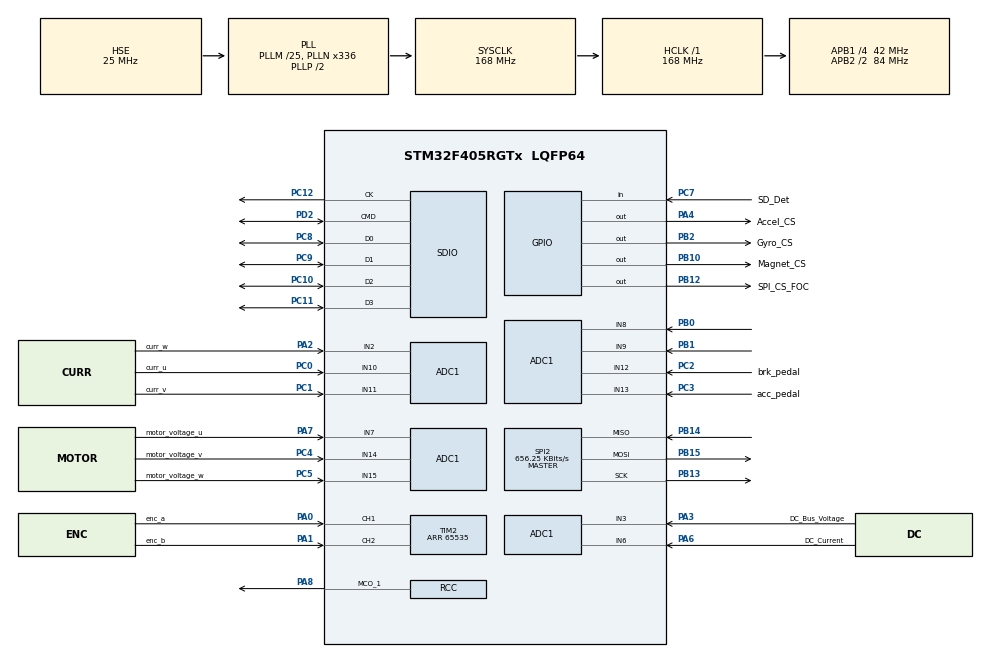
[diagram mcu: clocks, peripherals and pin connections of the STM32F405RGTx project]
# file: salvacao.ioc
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ADC1.Channel-0\#ChannelRegularConversion=ADC_CHANNEL_8
ADC1.Channel-1\#ChannelRegularConversion=ADC_CHANNEL_12
ADC1.Channel-12\#ChannelRegularConversion=ADC_CHANNEL_13
ADC1.Channel-13\#ChannelRegularConversion=ADC_CHANNEL_2
ADC1.Channel-14\#ChannelRegularConversion=ADC_CHANNEL_10
ADC1.Channel-15\#ChannelRegularConversion=ADC_CHANNEL_11
ADC1.Channel-16\#ChannelRegularConversion=ADC_CHANNEL_9
ADC1.Channel-17\#ChannelRegularConversion=ADC_CHANNEL_3
ADC1.Channel-18\#ChannelRegularConversion=ADC_CHANNEL_6
ADC1.Channel-19\#ChannelRegularConversion=ADC_CHANNEL_7
ADC1.Channel-20\#ChannelRegularConversion=ADC_CHANNEL_14
ADC1.Channel-21\#ChannelRegularConversion=ADC_CHANNEL_15
ADC1.ContinuousConvMode=ENABLE
ADC1.DMAContinuousRequests=ENABLE
ADC1.NbrOfConversion=12
ADC1.NbrOfConversionFlag=1
ADC1.Rank-0\#ChannelRegularConversion=1
ADC1.Rank-1\#ChannelRegularConversion=2
ADC1.Rank-12\#ChannelRegularConversion=3
ADC1.Rank-13\#ChannelRegularConversion=4
ADC1.Rank-14\#ChannelRegularConversion=5
ADC1.Rank-15\#ChannelRegularConversion=6
ADC1.Rank-16\#ChannelRegularConversion=7
ADC1.Rank-17\#ChannelRegularConversion=8
ADC1.Rank-18\#ChannelRegularConversion=9
ADC1.Rank-19\#ChannelRegularConversion=10
ADC1.Rank-20\#ChannelRegularConversion=11
ADC1.Rank-21\#ChannelRegularConversion=12
ADC1.SamplingTime-0\#ChannelRegularConversion=ADC_SAMPLETIME_3CYCLES
ADC1.SamplingTime-1\#ChannelRegularConversion=ADC_SAMPLETIME_3CYCLES
ADC1.SamplingTime-12\#ChannelRegularConversion=ADC_SAMPLETIME_3CYCLES
ADC1.SamplingTime-13\#ChannelRegularConversion=ADC_SAMPLETIME_3CYCLES
ADC1.SamplingTime-14\#ChannelRegularConversion=ADC_SAMPLETIME_3CYCLES
ADC1.SamplingTime-15\#ChannelRegularConversion=ADC_SAMPLETIME_3CYCLES
ADC1.SamplingTime-16\#ChannelRegularConversion=ADC_SAMPLETIME_3CYCLES
ADC1.SamplingTime-17\#ChannelRegularConversion=ADC_SAMPLETIME_3CYCLES
ADC1.SamplingTime-18\#ChannelRegularConversion=ADC_SAMPLETIME_3CYCLES
ADC1.SamplingTime-19\#ChannelRegularConversion=ADC_SAMPLETIME_3CYCLES
ADC1.SamplingTime-20\#ChannelRegularConversion=ADC_SAMPLETIME_3CYCLES
ADC1.SamplingTime-21\#ChannelRegularConversion=ADC_SAMPLETIME_3CYCLES
ADC1.ScanConvMode=ENABLE
ADC1.master=1
Dma.ADC1.0.Direction=DMA_PERIPH_TO_MEMORY
Dma.ADC1.0.FIFOMode=DMA_FIFOMODE_DISABLE
Dma.ADC1.0.Instance=DMA2_Stream0
Dma.ADC1.0.MemDataAlignment=DMA_MDATAALIGN_WORD
Dma.ADC1.0.MemInc=DMA_MINC_ENABLE
Dma.ADC1.0.Mode=DMA_CIRCULAR
Dma.ADC1.0.PeriphDataAlignment=DMA_PDATAALIGN_WORD
Dma.ADC1.0.PeriphInc=DMA_PINC_DISABLE
Dma.ADC1.0.Priority=DMA_PRIORITY_LOW
Dma.Request0=ADC1
Dma.Request1=SDIO_RX
Dma.Request2=SDIO_TX
Dma.SDIO_RX.1.Direction=DMA_PERIPH_TO_MEMORY
Dma.SDIO_RX.1.FIFOMode=DMA_FIFOMODE_ENABLE
Dma.SDIO_RX.1.FIFOThreshold=DMA_FIFO_THRESHOLD_FULL
Dma.SDIO_RX.1.Instance=DMA2_Stream3
Dma.SDIO_RX.1.MemBurst=DMA_MBURST_INC4
Dma.SDIO_RX.1.MemDataAlignment=DMA_MDATAALIGN_WORD
Dma.SDIO_RX.1.MemInc=DMA_MINC_ENABLE
Dma.SDIO_RX.1.Mode=DMA_PFCTRL
Dma.SDIO_RX.1.PeriphBurst=DMA_PBURST_INC4
Dma.SDIO_RX.1.PeriphDataAlignment=DMA_PDATAALIGN_WORD
Dma.SDIO_RX.1.PeriphInc=DMA_PINC_DISABLE
Dma.SDIO_RX.1.Priority=DMA_PRIORITY_LOW
Dma.SDIO_TX.2.Direction=DMA_MEMORY_TO_PERIPH
Dma.SDIO_TX.2.FIFOMode=DMA_FIFOMODE_ENABLE
Dma.SDIO_TX.2.FIFOThreshold=DMA_FIFO_THRESHOLD_FULL
Dma.SDIO_TX.2.Instance=DMA2_Stream6
Dma.SDIO_TX.2.MemBurst=DMA_MBURST_INC4
Dma.SDIO_TX.2.MemDataAlignment=DMA_MDATAALIGN_WORD
Dma.SDIO_TX.2.MemInc=DMA_MINC_ENABLE
Dma.SDIO_TX.2.Mode=DMA_PFCTRL
Dma.SDIO_TX.2.PeriphBurst=DMA_PBURST_INC4
Dma.SDIO_TX.2.PeriphDataAlignment=DMA_PDATAALIGN_WORD
Dma.SDIO_TX.2.PeriphInc=DMA_PINC_DISABLE
Dma.SDIO_TX.2.Priority=DMA_PRIORITY_LOW
FATFS.BSP.number=1
FATFS.USE_DMA_CODE_SD=1
FATFS._FS_LOCK=2
FATFS._MAX_SS=4096
FATFS._USE_LFN=1
FATFS0.BSP.STBoard=false
FATFS0.BSP.api=Unknown
FATFS0.BSP.i2caddr=0
FATFS0.BSP.instance=PC7
FATFS0.BSP.ip=GPIO
FATFS0.BSP.mode=Input
FATFS0.BSP.name=Detect_SDIO
FATFS0.BSP.solution=PC7
Mcu.Family=STM32F4
Mcu.Name=STM32F405RGTx
Mcu.Package=LQFP64
NVIC.DMA2_Stream0_IRQn=true\:0\:0\:false\:false\:true\:false\:true
NVIC.DMA2_Stream3_IRQn=true\:0\:0\:false\:false\:true\:false\:true
NVIC.DMA2_Stream6_IRQn=true\:0\:0\:false\:false\:true\:false\:true
NVIC.PriorityGroup=NVIC_PRIORITYGROUP_4
NVIC.SDIO_IRQn=true\:0\:0\:true\:false\:true\:true\:true
NVIC.TIM6_DAC_IRQn=true\:0\:0\:false\:false\:true\:true\:true
PA0-WKUP.GPIO_Label=enc_a
PA0-WKUP.Signal=S_TIM2_CH1_ETR
PA1.GPIO_Label=enc_b
PA1.Signal=S_TIM2_CH2
PA13.Mode=Trace_Asynchronous_SW
PA13.Signal=SYS_JTMS-SWDIO
PA14.Mode=Trace_Asynchronous_SW
PA14.Signal=SYS_JTCK-SWCLK
PA2.GPIO_Label=curr_w
PA2.Signal=ADCx_IN2
PA3.GPIO_Label=DC_Bus_Voltage
PA3.Signal=ADCx_IN3
PA4.GPIO_Label=Accel_CS
PA4.Signal=GPIO_Output
PA6.GPIO_Label=DC_Current
PA6.Signal=ADCx_IN6
PA7.GPIO_Label=motor_voltage_u
PA7.Signal=ADCx_IN7
PA8.Mode=Clock-out-1
PA8.Signal=RCC_MCO_1
PB0.Signal=ADCx_IN8
PB1.Signal=ADCx_IN9
PB10.GPIO_Label=Magnet_CS
PB10.Signal=GPIO_Output
PB12.GPIO_Label=SPI_CS_FOC
PB12.Signal=GPIO_Output
PB13.Mode=Full_Duplex_Master
PB13.Signal=SPI2_SCK
PB14.Mode=Full_Duplex_Master
PB14.Signal=SPI2_MISO
PB15.Mode=Full_Duplex_Master
PB15.Signal=SPI2_MOSI
PB2.GPIO_Label=Gyro_CS
PB2.Signal=GPIO_Output
PB3.Mode=Trace_Asynchronous_SW
PB3.Signal=SYS_JTDO-SWO
PC0.GPIO_Label=curr_u
PC0.Signal=ADCx_IN10
PC1.GPIO_Label=curr_v
PC1.Signal=ADCx_IN11
PC10.GPIO_PuPd=GPIO_NOPULL
PC10.Mode=SD_4_bits_Wide_bus
PC10.Signal=SDIO_D2
PC11.GPIO_PuPd=GPIO_NOPULL
PC11.Mode=SD_4_bits_Wide_bus
PC11.Signal=SDIO_D3
PC12.Mode=SD_4_bits_Wide_bus
PC12.Signal=SDIO_CK
PC14-OSC32_IN.Mode=LSE-External-Oscillator
PC14-OSC32_IN.Signal=RCC_OSC32_IN
PC15-OSC32_OUT.Mode=LSE-External-Oscillator
PC15-OSC32_OUT.Signal=RCC_OSC32_OUT
PC2.GPIO_Label=brk_pedal
PC2.Signal=ADCx_IN12
PC3.GPIO_Label=acc_pedal
PC3.Signal=ADCx_IN13
PC4.GPIO_Label=motor_voltage_v
PC4.Signal=ADCx_IN14
PC5.GPIO_Label=motor_voltage_w
PC5.Signal=ADCx_IN15
PC7.GPIO_Label=SD_Det
PC7.GPIO_PuPd=GPIO_NOPULL
PC7.Signal=GPIO_Input
PC8.GPIO_PuPd=GPIO_PULLUP
PC8.Mode=SD_4_bits_Wide_bus
PC8.Signal=SDIO_D0
PC9.GPIO_PuPd=GPIO_NOPULL
PC9.Mode=SD_4_bits_Wide_bus
PC9.Signal=SDIO_D1
PD2.GPIO_PuPd=GPIO_PULLUP
PD2.Mode=SD_4_bits_Wide_bus
PD2.Signal=SDIO_CMD
PH0-OSC_IN.Mode=HSE-External-Oscillator
PH0-OSC_IN.Signal=RCC_OSC_IN
PH1-OSC_OUT.Mode=HSE-External-Oscillator
PH1-OSC_OUT.Signal=RCC_OSC_OUT
ProjectManager.HeapSize=0x8000
ProjectManager.StackSize=0x8000
ProjectManager.TargetToolchain=STM32CubeIDE
RCC.48MHZClocksFreq_Value=48000000
RCC.AHBFreq_Value=168000000
RCC.APB1CLKDivider=RCC_HCLK_DIV4
RCC.APB1Freq_Value=42000000
RCC.APB1TimFreq_Value=84000000
RCC.APB2CLKDivider=RCC_HCLK_DIV2
RCC.APB2Freq_Value=84000000
RCC.APB2TimFreq_Value=168000000
RCC.CortexFreq_Value=168000000
RCC.HCLKFreq_Value=168000000
RCC.HSE_VALUE=25000000
RCC.HSI_VALUE=16000000
RCC.PLLM=25
RCC.PLLN=336
RCC.PLLQ=7
RCC.PLLSourceVirtual=RCC_PLLSOURCE_HSE
RCC.RCC_MCO1Source=RCC_MCO1SOURCE_HSE
RCC.RCC_MCODiv1=RCC_MCODIV_2
RCC.SYSCLKFreq_VALUE=168000000
RCC.SYSCLKSource=RCC_SYSCLKSOURCE_PLLCLK
RCC.VCOOutputFreq_Value=336000000
SDIO.ClockDiv=1
SH.ADCx_IN10.0=ADC1_IN10,IN10
SH.ADCx_IN11.0=ADC1_IN11,IN11
SH.ADCx_IN12.0=ADC1_IN12,IN12
SH.ADCx_IN13.0=ADC1_IN13,IN13
SH.ADCx_IN14.0=ADC1_IN14,IN14
SH.ADCx_IN15.0=ADC1_IN15,IN15
SH.ADCx_IN2.0=ADC1_IN2,IN2
SH.ADCx_IN3.0=ADC1_IN3,IN3
SH.ADCx_IN6.0=ADC1_IN6,IN6
SH.ADCx_IN7.0=ADC1_IN7,IN7
SH.ADCx_IN8.0=ADC1_IN8,IN8
SH.ADCx_IN9.0=ADC1_IN9,IN9
SH.S_TIM2_CH1_ETR.0=TIM2_CH1,Encoder_Interface
SH.S_TIM2_CH2.0=TIM2_CH2,Encoder_Interface
SPI2.BaudRatePrescaler=SPI_BAUDRATEPRESCALER_64
SPI2.CLKPhase=SPI_PHASE_2EDGE
SPI2.CLKPolarity=SPI_POLARITY_HIGH
SPI2.CalculateBaudRate=656.25 KBits/s
SPI2.Direction=SPI_DIRECTION_2LINES
SPI2.Mode=SPI_MODE_MASTER
SPI2.VirtualType=VM_MASTER
TIM2.EncoderMode=TIM_ENCODERMODE_TI12
TIM2.Period=65535
TIM6.Period=2000
TIM6.Prescaler=42000
TIM6.TIM_MasterOutputTrigger=TIM_TRGO_UPDATE
VP_FATFS_VS_SDIO.Mode=SDIO
VP_TIM6_VS_ClockSourceINT.Mode=Enable_Timer
board=custom

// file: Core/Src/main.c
/* USER CODE BEGIN Header */
/**
  ******************************************************************************
  * @file           : main.c
  * @brief          : Main program body
  ******************************************************************************
  * @attention
  *
  * <h2><center>&copy; Copyright (c) 2020 STMicroelectronics.
  * All rights reserved.</center></h2>
  *
  * This software component is licensed by ST under BSD 3-Clause license,
  * the "License"; You may not use this file except in compliance with the
  * License. You may obtain a copy of the License at:
  *                        opensource.org/licenses/BSD-3-Clause
  *
  ******************************************************************************
  */
/* USER CODE END Header */

#include "main.h"
#include "fatfs.h"

/* USER CODE BEGIN Includes */
#include "stdio.h"
#include "sd_wr.h"
#include "IMU_read.h"
#include "encoderMode.h"
#include "adcUnitConversion.h"
#include "FOC_lib.h"
/* USER CODE END Includes */

/* USER CODE BEGIN PD */

#define	NR_ADC_CHANNELS 12 //Nº de channels adc
#define TICK_RATE 1 //milisecond

/* USER CODE END PD */

ADC_HandleTypeDef hadc1;
DMA_HandleTypeDef hdma_adc1;

SD_HandleTypeDef hsd;
DMA_HandleTypeDef hdma_sdio_rx;
DMA_HandleTypeDef hdma_sdio_tx;

SPI_HandleTypeDef hspi2;

TIM_HandleTypeDef htim2;
TIM_HandleTypeDef htim6;

/* USER CODE BEGIN PV */

volatile unsigned long SystemTick=0;
volatile unsigned long __unix_ms=0;
volatile unsigned long __unix_sec=0;

uint32_t adc_dma[NR_ADC_CHANNELS], buffer_dma[NR_ADC_CHANNELS];

//SD file variables
	FATFS fs;  // file system
	FIL fil, fil2, fil3;  // file
	FRESULT fresult;  // to store the result
	char buffer[512]; // to store data

	UINT br, bw;   // file read/write count

	/* capacity related variables */
	//DWORD fre_clust;
	DWORD total, free_space;

//Encoder mode variables
	uint32_t counter1 = 0, counter2 = 0;
	uint32_t tick = 0;
	float speed = 0;

//IMU accelerometer data
	int accel_data[3];
//IMU accelerometer data
	int gyro_data[3];
	long int c1;

	float dc_current, current_ph1, current_ph2, current_ph3, dc_voltage, voltage_ph1, voltage_ph2, voltage_ph3,  motor_temp, conv_temp, acc_pedal , brk_pedal;

	float rms_current_ph1[10] = {-1,-1,-1,-1,-1,-1,-1,-1,-1,-1};
	float rms_current_ph2[10] = {-1,-1,-1,-1,-1,-1,-1,-1,-1,-1};
	float rms_current_ph3[10] = {-1,-1,-1,-1,-1,-1,-1,-1,-1,-1};
	float rms_voltage[10]     = {-1,-1,-1,-1,-1,-1,-1,-1,-1,-1};

	float current1_rms = 0;
	float current2_rms = 0;
	float current3_rms = 0;
	float voltage1_rms = 0;
	float voltage2_rms = 0;
	float voltage3_rms = 0;

	int f = 0;

//encoder
/*	int stateA = 0, stateB = 0, stateM = 0, pstateA = 0, pstateB = 0, pstate = 0, pulses = 0;
	int dir = 0; // 0 forward -1 otherwise*/

	char stamp[100];

	//teste
	uint32_t time2;

//microsegundos
	uint32_t micro = 0, mili = 0, seg = 0;

/* USER CODE END PV */

void SystemClock_Config(void);
static void MX_GPIO_Init(void);
static void MX_DMA_Init(void);
static void MX_SPI2_Init(void);
static void MX_ADC1_Init(void);
static void MX_SDIO_SD_Init(void);
static void MX_TIM6_Init(void);
static void MX_TIM2_Init(void);

/* USER CODE BEGIN 0 */

void HAL_ADC_ConvCpltCallback(ADC_HandleTypeDef* hadc)
{
	//printf("dma timer = %lu\n", HAL_GetTick()-time2);
	if(hadc->Instance == ADC1){
		for(int i=0; i < NR_ADC_CHANNELS; i++)
			{
				adc_dma[i]=buffer_dma[i];
			}
	}
	//time2 = HAL_GetTick();
}

void HAL_TIM_PeriodElapsedCallback(TIM_HandleTypeDef *htim){

	//UNUSED(htim); será preciso?

	//counter2 = __HAL_TIM_GET_COUNTER(&htim2);
	//printf("%lu\n", HAL_GetTick());
	if(htim->Instance== TIM6){
		printf("kay\n");
		speed = motorSpeed(&counter1, &tick, htim2);
	}
	/*if(htim->Instance == TIM7) {
		//printf("hello7\n");
		micro++;
		if(micro >= 1000){
			micro -= 1000;
			if(mili == 999){
				mili = 0;
				seg++;
			}
			else mili++;
		}
	}*/

	/* passa a fazer-se aqui?
	sprintf(str, "%f ", speed);
	update_file("encoder_data.txt", str, get_timestamp(&hrtc, &currentTime, &currentDate), stamp, &(fil[12]), &bw); */

	/*float T = 0.25; //assumindo que periodo é 250ms
	speed = ((pulses/8)*60)/T;
	pulses = 0;*/

}

/* USER CODE END 0 */

int main(void)
{

  /* MCU Configuration--------------------------------------------------------*/

  /* Reset of all peripherals, Initializes the Flash interface and the Systick. */
  HAL_Init();

  /* Configure the system clock */
  SystemClock_Config();

  /* Initialize all configured peripherals */
  MX_GPIO_Init();
  MX_DMA_Init();
  MX_SPI2_Init();
  MX_ADC1_Init();
  MX_SDIO_SD_Init();
  MX_FATFS_Init();
  MX_TIM6_Init();
  MX_TIM2_Init();
  /* USER CODE BEGIN 2 */

  HAL_GPIO_WritePin(Accel_CS_GPIO_Port, Accel_CS_Pin, SET);
  HAL_GPIO_WritePin(Gyro_CS_GPIO_Port, Gyro_CS_Pin, SET);
  HAL_GPIO_WritePin(Magnet_CS_GPIO_Port, Magnet_CS_Pin, SET);
  HAL_GPIO_WritePin(SPI_CS_FOC_GPIO_Port, SPI_CS_FOC_Pin, SET);

  foc_ic_config(&hspi2);

  fresult=mount_card(&fs);

  char str2[30];

  IMU_config(&hspi2);

  HAL_TIM_Base_Start_IT(&htim6);
  //HAL_TIM_Base_Start_IT(&htim7);

  //Initialize encoder mode
  HAL_TIM_Encoder_Start(&htim2, TIM_CHANNEL_ALL);
  tick = HAL_GetTick();
  counter1 = __HAL_TIM_GET_COUNTER(&htim2);

  uint8_t aux[5], aux2[1], aux3[1], str3[4], str[5];
  //uint8_t ref[5];
    aux[0]=0b10000001;
    for(int i=1; i<=4; i++){
  	  aux[i]=0b00000000;
    }
    aux2[0]=0b00000000;

    time2 = HAL_GetTick();
	HAL_ADC_Start_DMA(&hadc1, buffer_dma, NR_ADC_CHANNELS);

  /* USER CODE END 2 */

  /* Infinite loop */
  while (1)
  {

    /* USER CODE BEGIN 3 */

	  printf("acc %f\n", acc_pedal);
	  if(brk_pedal > 15){
		  foc_ic_send_torque(&hspi2, 0, -1);
	  }
	  else{
		  foc_ic_send_torque(&hspi2, 30000, acc_pedal);
	  }

	  uint32_t time1 = HAL_GetTick();

	  //printf("Microssegundos = %lu\n", seg);
	  uint32_t read=adc_dma[0];
	  motor_temp = motorTemp(read);

	  read=adc_dma[1];
	  brk_pedal = pedalPos(read);

	  read=adc_dma[2];
	  acc_pedal = pedalPos(read);

	  read=adc_dma[3];
	  current_ph1 = motorCurrent(read);
	  rms_current_ph1[f] = current_ph1*current_ph1;

	  read=adc_dma[4];
	  current_ph2 = motorCurrent(read);
	  rms_current_ph2[f] = current_ph2*current_ph2;

	  read=adc_dma[5];
	  current_ph3 = motorCurrent(read);
	  rms_current_ph3[f] = current_ph3*current_ph3;

	  read=adc_dma[6];
	  conv_temp = igbtTemp(read);

	  read=adc_dma[7];
	  dc_voltage=voltageDC(read);

	  read=adc_dma[8];
	  dc_current=motorCurrent(read); //função corrente dc?

	  read=adc_dma[9];
	  voltage_ph1=voltageAC(read);

	  read=adc_dma[10];
	  voltage_ph2=voltageAC(read);

	  read=adc_dma[11];
	  voltage_ph3=voltageAC(read);

	 /* //leitura do encoder
	  read = adc_dma[12]; //encoder signal A
	  stateA = stateValue(read);

	  read = adc_dma[13]; //encoder signal B
	  stateB = stateValue(read);

	  if((stateA != pstateA) || (stateB != pstateB)){
		  if(stateA != pstateA){
			  pstateA = stateA;
		  }
		  if (stateB != pstateB){
			  pstateB = stateB;
		  }
		  updateCounter(stateA, stateB, &pstate, &dir, &pulses);
	  }

	  if(f==4){
		  current1_rms = rms(rms_current_ph1);
		  f=0;
	  }
	  else{
		  f++;
	  }*/

/*
 *
	  if(acc>50){
		  ref[0]
		  HAL_GPIO_WritePin(SPI_CS_FOC_GPIO_Port, SPI_CS_FOC_Pin, RESET);
		  HAL_SPI_Transmit(&hspi2, ref, 5, 1000);
		  HAL_GPIO_WritePin(SPI_CS_FOC_GPIO_Port, SPI_CS_FOC_Pin, SET);
	  }
	  else if(brk>50)*/

	  HAL_GPIO_WritePin(SPI_CS_FOC_GPIO_Port, SPI_CS_FOC_Pin, RESET);
	  HAL_SPI_Transmit(&hspi2, aux, 5, 1000);
	  HAL_GPIO_WritePin(SPI_CS_FOC_GPIO_Port, SPI_CS_FOC_Pin, SET);

	  HAL_GPIO_WritePin(SPI_CS_FOC_GPIO_Port, SPI_CS_FOC_Pin, RESET);
	  HAL_SPI_Transmit(&hspi2, aux2, 1, 1000);
	  HAL_SPI_Receive(&hspi2, str, 4, 1000);
	  HAL_GPIO_WritePin(SPI_CS_FOC_GPIO_Port, SPI_CS_FOC_Pin, SET);
	  //printf("%d %d %d %d\n", str[0], str[1], str[2], str[3]);

	  //ler velocidades do tmc
	  aux3[0]=0x6A;
	  HAL_GPIO_WritePin(SPI_CS_FOC_GPIO_Port, SPI_CS_FOC_Pin, RESET);
	  HAL_SPI_Transmit(&hspi2, aux3, 1, 1000);
	  HAL_SPI_Receive(&hspi2, str3, 4, 1000);
	  HAL_GPIO_WritePin(SPI_CS_FOC_GPIO_Port, SPI_CS_FOC_Pin, SET);
	  //printf("PID VELOCITY ACTUAL: %d %d %d %d\n", str3[0], str3[1], str3[2], str3[3]);

	  aux3[0]=0x22;
	  HAL_GPIO_WritePin(SPI_CS_FOC_GPIO_Port, SPI_CS_FOC_Pin, RESET);
	  HAL_SPI_Transmit(&hspi2, aux3, 1, 1000);
	  HAL_SPI_Receive(&hspi2, str3, 4, 1000);
	  HAL_GPIO_WritePin(SPI_CS_FOC_GPIO_Port, SPI_CS_FOC_Pin, SET);
	  printf("OPENLOOP VELOCITY ACTUAL: %d %d %d %d\n", str3[0], str3[1], str3[2], str3[3]);

	  aux3[0]=0x41;
	  HAL_GPIO_WritePin(SPI_CS_FOC_GPIO_Port, SPI_CS_FOC_Pin, RESET);
	  HAL_SPI_Transmit(&hspi2, aux3, 1, 1000);
	  HAL_SPI_Receive(&hspi2, str3, 4, 1000);
	  HAL_GPIO_WritePin(SPI_CS_FOC_GPIO_Port, SPI_CS_FOC_Pin, SET);
	  //printf("AENC DECODER COUNT: %d %d %d %d\n", str3[0], str3[1], str3[2], str3[3]);	   */

	  sprintf(str2,"%f ", brk_pedal);
	  sprintf(stamp, "%lu:%lu",  __unix_sec,  __unix_ms);
	  update_file("brake.txt", str2, stamp, "", &fil2, &bw);
	  stamp[0]='\0';

	  sprintf(str2,"%f ", acc_pedal);
	  sprintf(stamp, "%lu:%lu",  __unix_sec,  __unix_ms);
	  update_file("throttle.txt", str2, stamp, "", &fil2, &bw);
	  stamp[0]='\0';

	  IMU_acc_read(&hspi2, accel_data);
	  for(int i=0; i<=2; i++){
		  sprintf(str2, "accel[%d] - %d ", i, accel_data[i]);
		  sprintf(stamp, "%lu:%lu",  __unix_sec,  __unix_ms);
		  update_file("acc.txt", str2, stamp, "", &fil2, &bw);
		  stamp[0]='\0';
	  }

	  IMU_gyro_read(&hspi2, gyro_data);
	  for(int i=0; i<=2; i++){
		  sprintf(str2, "gyro[%d] - %d ", i, gyro_data[i]);
		  sprintf(stamp, "%lu:%lu",  __unix_sec,  __unix_ms);
		  update_file("gyro.txt", str2, stamp, "", &fil2, &bw);
		  stamp[0]='\0';
	  }

	  printf("tempo de ciclo = %lu\n", (HAL_GetTick() - time1));

  }

  /* USER CODE END 3 */
}

void SystemClock_Config(void)
{
  RCC_OscInitTypeDef RCC_OscInitStruct = {0};
  RCC_ClkInitTypeDef RCC_ClkInitStruct = {0};

  /** Configure the main internal regulator output voltage
  */
  __HAL_RCC_PWR_CLK_ENABLE();
  __HAL_PWR_VOLTAGESCALING_CONFIG(PWR_REGULATOR_VOLTAGE_SCALE1);
  /** Initializes the CPU, AHB and APB busses clocks
  */
  RCC_OscInitStruct.OscillatorType = RCC_OSCILLATORTYPE_HSE;
  RCC_OscInitStruct.HSEState = RCC_HSE_ON;
  RCC_OscInitStruct.PLL.PLLState = RCC_PLL_ON;
  RCC_OscInitStruct.PLL.PLLSource = RCC_PLLSOURCE_HSE;
  RCC_OscInitStruct.PLL.PLLM = 25;
  RCC_OscInitStruct.PLL.PLLN = 336;
  RCC_OscInitStruct.PLL.PLLP = RCC_PLLP_DIV2;
  RCC_OscInitStruct.PLL.PLLQ = 7;
  if (HAL_RCC_OscConfig(&RCC_OscInitStruct) != HAL_OK)
  {
    Error_Handler();
  }
  /** Initializes the CPU, AHB and APB busses clocks
  */
  RCC_ClkInitStruct.ClockType = RCC_CLOCKTYPE_HCLK|RCC_CLOCKTYPE_SYSCLK
                              |RCC_CLOCKTYPE_PCLK1|RCC_CLOCKTYPE_PCLK2;
  RCC_ClkInitStruct.SYSCLKSource = RCC_SYSCLKSOURCE_PLLCLK;
  RCC_ClkInitStruct.AHBCLKDivider = RCC_SYSCLK_DIV1;
  RCC_ClkInitStruct.APB1CLKDivider = RCC_HCLK_DIV4;
  RCC_ClkInitStruct.APB2CLKDivider = RCC_HCLK_DIV2;

  if (HAL_RCC_ClockConfig(&RCC_ClkInitStruct, FLASH_LATENCY_5) != HAL_OK)
  {
    Error_Handler();
  }
  HAL_RCC_MCOConfig(RCC_MCO1, RCC_MCO1SOURCE_HSE, RCC_MCODIV_2);
}

static void MX_ADC1_Init(void)
{

  ADC_ChannelConfTypeDef sConfig = {0};

  /** Configure the global features of the ADC (Clock, Resolution, Data Alignment and number of conversion)
  */
  hadc1.Instance = ADC1;
  hadc1.Init.ClockPrescaler = ADC_CLOCK_SYNC_PCLK_DIV4;
  hadc1.Init.Resolution = ADC_RESOLUTION_12B;
  hadc1.Init.ScanConvMode = ENABLE;
  hadc1.Init.ContinuousConvMode = ENABLE;
  hadc1.Init.DiscontinuousConvMode = DISABLE;
  hadc1.Init.ExternalTrigConvEdge = ADC_EXTERNALTRIGCONVEDGE_NONE;
  hadc1.Init.ExternalTrigConv = ADC_SOFTWARE_START;
  hadc1.Init.DataAlign = ADC_DATAALIGN_RIGHT;
  hadc1.Init.NbrOfConversion = 12;
  hadc1.Init.DMAContinuousRequests = ENABLE;
  hadc1.Init.EOCSelection = ADC_EOC_SINGLE_CONV;
  if (HAL_ADC_Init(&hadc1) != HAL_OK)
  {
    Error_Handler();
  }
  /** Configure for the selected ADC regular channel its corresponding rank in the sequencer and its sample time.
  */
  sConfig.Channel = ADC_CHANNEL_8;
  sConfig.Rank = 1;
  sConfig.SamplingTime = ADC_SAMPLETIME_3CYCLES;
  if (HAL_ADC_ConfigChannel(&hadc1, &sConfig) != HAL_OK)
  {
    Error_Handler();
  }
  /** Configure for the selected ADC regular channel its corresponding rank in the sequencer and its sample time.
  */
  sConfig.Channel = ADC_CHANNEL_12;
  sConfig.Rank = 2;
  if (HAL_ADC_ConfigChannel(&hadc1, &sConfig) != HAL_OK)
  {
    Error_Handler();
  }
  /** Configure for the selected ADC regular channel its corresponding rank in the sequencer and its sample time.
  */
  sConfig.Channel = ADC_CHANNEL_13;
  sConfig.Rank = 3;
  if (HAL_ADC_ConfigChannel(&hadc1, &sConfig) != HAL_OK)
  {
    Error_Handler();
  }
  /** Configure for the selected ADC regular channel its corresponding rank in the sequencer and its sample time.
  */
  sConfig.Channel = ADC_CHANNEL_2;
  sConfig.Rank = 4;
  if (HAL_ADC_ConfigChannel(&hadc1, &sConfig) != HAL_OK)
  {
    Error_Handler();
  }
  /** Configure for the selected ADC regular channel its corresponding rank in the sequencer and its sample time.
  */
  sConfig.Channel = ADC_CHANNEL_10;
  sConfig.Rank = 5;
  if (HAL_ADC_ConfigChannel(&hadc1, &sConfig) != HAL_OK)
  {
    Error_Handler();
  }
  /** Configure for the selected ADC regular channel its corresponding rank in the sequencer and its sample time.
  */
  sConfig.Channel = ADC_CHANNEL_11;
  sConfig.Rank = 6;
  if (HAL_ADC_ConfigChannel(&hadc1, &sConfig) != HAL_OK)
  {
    Error_Handler();
  }
  /** Configure for the selected ADC regular channel its corresponding rank in the sequencer and its sample time.
  */
  sConfig.Channel = ADC_CHANNEL_9;
  sConfig.Rank = 7;
  if (HAL_ADC_ConfigChannel(&hadc1, &sConfig) != HAL_OK)
  {
    Error_Handler();
  }
  /** Configure for the selected ADC regular channel its corresponding rank in the sequencer and its sample time.
  */
  sConfig.Channel = ADC_CHANNEL_3;
  sConfig.Rank = 8;
  if (HAL_ADC_ConfigChannel(&hadc1, &sConfig) != HAL_OK)
  {
    Error_Handler();
  }
  /** Configure for the selected ADC regular channel its corresponding rank in the sequencer and its sample time.
  */
  sConfig.Channel = ADC_CHANNEL_6;
  sConfig.Rank = 9;
  if (HAL_ADC_ConfigChannel(&hadc1, &sConfig) != HAL_OK)
  {
    Error_Handler();
  }
  /** Configure for the selected ADC regular channel its corresponding rank in the sequencer and its sample time.
  */
  sConfig.Channel = ADC_CHANNEL_7;
  sConfig.Rank = 10;
  if (HAL_ADC_ConfigChannel(&hadc1, &sConfig) != HAL_OK)
  {
    Error_Handler();
  }
  /** Configure for the selected ADC regular channel its corresponding rank in the sequencer and its sample time.
  */
  sConfig.Channel = ADC_CHANNEL_14;
  sConfig.Rank = 11;
  if (HAL_ADC_ConfigChannel(&hadc1, &sConfig) != HAL_OK)
  {
    Error_Handler();
  }
  /** Configure for the selected ADC regular channel its corresponding rank in the sequencer and its sample time.
  */
  sConfig.Channel = ADC_CHANNEL_15;
  sConfig.Rank = 12;
  if (HAL_ADC_ConfigChannel(&hadc1, &sConfig) != HAL_OK)
  {
    Error_Handler();
  }

}

static void MX_SDIO_SD_Init(void)
{

  hsd.Instance = SDIO;
  hsd.Init.ClockEdge = SDIO_CLOCK_EDGE_RISING;
  hsd.Init.ClockBypass = SDIO_CLOCK_BYPASS_DISABLE;
  hsd.Init.ClockPowerSave = SDIO_CLOCK_POWER_SAVE_DISABLE;
  hsd.Init.BusWide = SDIO_BUS_WIDE_1B;
  hsd.Init.HardwareFlowControl = SDIO_HARDWARE_FLOW_CONTROL_DISABLE;
  hsd.Init.ClockDiv = 1;

}

static void MX_SPI2_Init(void)
{

  /* SPI2 parameter configuration*/
  hspi2.Instance = SPI2;
  hspi2.Init.Mode = SPI_MODE_MASTER;
  hspi2.Init.Direction = SPI_DIRECTION_2LINES;
  hspi2.Init.DataSize = SPI_DATASIZE_8BIT;
  hspi2.Init.CLKPolarity = SPI_POLARITY_HIGH;
  hspi2.Init.CLKPhase = SPI_PHASE_2EDGE;
  hspi2.Init.NSS = SPI_NSS_SOFT;
  hspi2.Init.BaudRatePrescaler = SPI_BAUDRATEPRESCALER_64;
  hspi2.Init.FirstBit = SPI_FIRSTBIT_MSB;
  hspi2.Init.TIMode = SPI_TIMODE_DISABLE;
  hspi2.Init.CRCCalculation = SPI_CRCCALCULATION_DISABLE;
  hspi2.Init.CRCPolynomial = 10;
  if (HAL_SPI_Init(&hspi2) != HAL_OK)
  {
    Error_Handler();
  }

}

static void MX_TIM2_Init(void)
{

  TIM_Encoder_InitTypeDef sConfig = {0};
  TIM_MasterConfigTypeDef sMasterConfig = {0};

  htim2.Instance = TIM2;
  htim2.Init.Prescaler = 0;
  htim2.Init.CounterMode = TIM_COUNTERMODE_UP;
  htim2.Init.Period = 65535;
  htim2.Init.ClockDivision = TIM_CLOCKDIVISION_DIV1;
  htim2.Init.AutoReloadPreload = TIM_AUTORELOAD_PRELOAD_DISABLE;
  sConfig.EncoderMode = TIM_ENCODERMODE_TI12;
  sConfig.IC1Polarity = TIM_ICPOLARITY_RISING;
  sConfig.IC1Selection = TIM_ICSELECTION_DIRECTTI;
  sConfig.IC1Prescaler = TIM_ICPSC_DIV1;
  sConfig.IC1Filter = 0;
  sConfig.IC2Polarity = TIM_ICPOLARITY_RISING;
  sConfig.IC2Selection = TIM_ICSELECTION_DIRECTTI;
  sConfig.IC2Prescaler = TIM_ICPSC_DIV1;
  sConfig.IC2Filter = 0;
  if (HAL_TIM_Encoder_Init(&htim2, &sConfig) != HAL_OK)
  {
    Error_Handler();
  }
  sMasterConfig.MasterOutputTrigger = TIM_TRGO_RESET;
  sMasterConfig.MasterSlaveMode = TIM_MASTERSLAVEMODE_DISABLE;
  if (HAL_TIMEx_MasterConfigSynchronization(&htim2, &sMasterConfig) != HAL_OK)
  {
    Error_Handler();
  }

}

static void MX_TIM6_Init(void)
{

  TIM_MasterConfigTypeDef sMasterConfig = {0};

  htim6.Instance = TIM6;
  htim6.Init.Prescaler = 42000;
  htim6.Init.CounterMode = TIM_COUNTERMODE_UP;
  htim6.Init.Period = 2000;
  htim6.Init.AutoReloadPreload = TIM_AUTORELOAD_PRELOAD_DISABLE;
  if (HAL_TIM_Base_Init(&htim6) != HAL_OK)
  {
    Error_Handler();
  }
  sMasterConfig.MasterOutputTrigger = TIM_TRGO_UPDATE;
  sMasterConfig.MasterSlaveMode = TIM_MASTERSLAVEMODE_DISABLE;
  if (HAL_TIMEx_MasterConfigSynchronization(&htim6, &sMasterConfig) != HAL_OK)
  {
    Error_Handler();
  }

}

static void MX_DMA_Init(void)
{

  /* DMA controller clock enable */
  __HAL_RCC_DMA2_CLK_ENABLE();

  /* DMA interrupt init */
  /* DMA2_Stream0_IRQn interrupt configuration */
  HAL_NVIC_SetPriority(DMA2_Stream0_IRQn, 0, 0);
  HAL_NVIC_EnableIRQ(DMA2_Stream0_IRQn);
  /* DMA2_Stream3_IRQn interrupt configuration */
  HAL_NVIC_SetPriority(DMA2_Stream3_IRQn, 0, 0);
  HAL_NVIC_EnableIRQ(DMA2_Stream3_IRQn);
  /* DMA2_Stream6_IRQn interrupt configuration */
  HAL_NVIC_SetPriority(DMA2_Stream6_IRQn, 0, 0);
  HAL_NVIC_EnableIRQ(DMA2_Stream6_IRQn);

}

static void MX_GPIO_Init(void)
{
  GPIO_InitTypeDef GPIO_InitStruct = {0};

  /* GPIO Ports Clock Enable */
  __HAL_RCC_GPIOC_CLK_ENABLE();
  __HAL_RCC_GPIOH_CLK_ENABLE();
  __HAL_RCC_GPIOA_CLK_ENABLE();
  __HAL_RCC_GPIOB_CLK_ENABLE();
  __HAL_RCC_GPIOD_CLK_ENABLE();

  /*Configure GPIO pin Output Level */
  HAL_GPIO_WritePin(Accel_CS_GPIO_Port, Accel_CS_Pin, GPIO_PIN_RESET);

  /*Configure GPIO pin Output Level */
  HAL_GPIO_WritePin(GPIOB, Gyro_CS_Pin|Magnet_CS_Pin|SPI_CS_FOC_Pin, GPIO_PIN_RESET);

  /*Configure GPIO pin : Accel_CS_Pin */
  GPIO_InitStruct.Pin = Accel_CS_Pin;
  GPIO_InitStruct.Mode = GPIO_MODE_OUTPUT_PP;
  GPIO_InitStruct.Pull = GPIO_NOPULL;
  GPIO_InitStruct.Speed = GPIO_SPEED_FREQ_LOW;
  HAL_GPIO_Init(Accel_CS_GPIO_Port, &GPIO_InitStruct);

  /*Configure GPIO pins : Gyro_CS_Pin Magnet_CS_Pin SPI_CS_FOC_Pin */
  GPIO_InitStruct.Pin = Gyro_CS_Pin|Magnet_CS_Pin|SPI_CS_FOC_Pin;
  GPIO_InitStruct.Mode = GPIO_MODE_OUTPUT_PP;
  GPIO_InitStruct.Pull = GPIO_NOPULL;
  GPIO_InitStruct.Speed = GPIO_SPEED_FREQ_LOW;
  HAL_GPIO_Init(GPIOB, &GPIO_InitStruct);

  /*Configure GPIO pin : SD_Det_Pin */
  GPIO_InitStruct.Pin = SD_Det_Pin;
  GPIO_InitStruct.Mode = GPIO_MODE_INPUT;
  GPIO_InitStruct.Pull = GPIO_NOPULL;
  HAL_GPIO_Init(SD_Det_GPIO_Port, &GPIO_InitStruct);

  /*Configure GPIO pin : PA8 */
  GPIO_InitStruct.Pin = GPIO_PIN_8;
  GPIO_InitStruct.Mode = GPIO_MODE_AF_PP;
  GPIO_InitStruct.Pull = GPIO_NOPULL;
  GPIO_InitStruct.Speed = GPIO_SPEED_FREQ_LOW;
  GPIO_InitStruct.Alternate = GPIO_AF0_MCO;
  HAL_GPIO_Init(GPIOA, &GPIO_InitStruct);

}

/* USER CODE BEGIN 4 */

int __io_putchar(int ch){
	ITM_SendChar(ch);
	return ch;
}

int _write(int file, char *ptr, int len){
	int DataIdx;

	for(DataIdx = 0; DataIdx < len; DataIdx++){
		__io_putchar(*ptr++);
	}
	return len;
}
/* USER CODE END 4 */

void Error_Handler(void)
{
}

/************************ (C) COPYRIGHT STMicroelectronics *****END OF FILE****/
